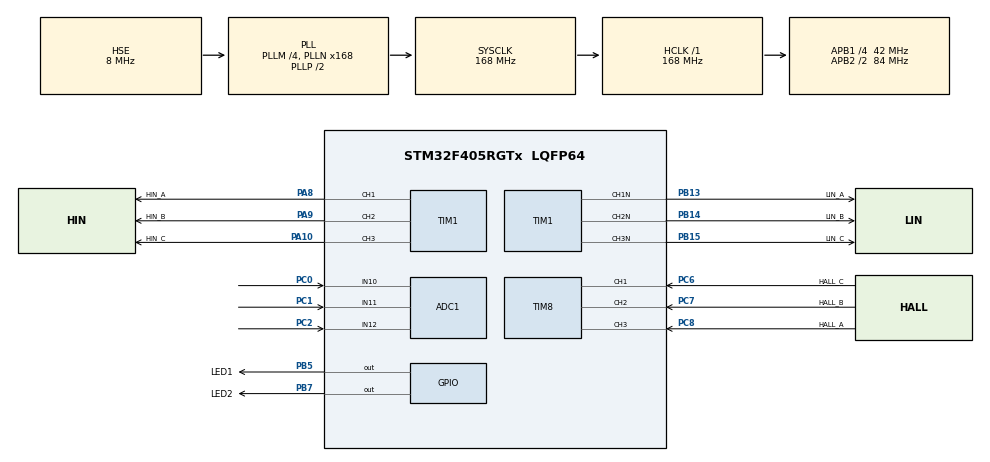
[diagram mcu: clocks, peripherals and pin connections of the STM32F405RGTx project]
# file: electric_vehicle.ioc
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ADC1.Channel-0\#ChannelRegularConversion=ADC_CHANNEL_10
ADC1.Channel-4\#ChannelInjectedConversion=ADC_CHANNEL_10
ADC1.Channel-5\#ChannelInjectedConversion=ADC_CHANNEL_11
ADC1.Channel-6\#ChannelInjectedConversion=ADC_CHANNEL_12
ADC1.DataAlign=ADC_DATAALIGN_LEFT
ADC1.ExternalTrigInjecConv=ADC_EXTERNALTRIGINJECCONV_T1_CC4
ADC1.InjNumberOfConversion=3
ADC1.InjectedConvMode=Discontinuous
ADC1.InjectedOffset-4\#ChannelInjectedConversion=0
ADC1.InjectedOffset-5\#ChannelInjectedConversion=0
ADC1.InjectedOffset-6\#ChannelInjectedConversion=0
ADC1.InjectedRank-4\#ChannelInjectedConversion=1
ADC1.InjectedRank-5\#ChannelInjectedConversion=2
ADC1.InjectedRank-6\#ChannelInjectedConversion=3
ADC1.NbrOfConversion=1
ADC1.NbrOfConversionFlag=1
ADC1.Rank-0\#ChannelRegularConversion=1
ADC1.SamplingTime-0\#ChannelRegularConversion=ADC_SAMPLETIME_3CYCLES
ADC1.SamplingTime-4\#ChannelInjectedConversion=ADC_SAMPLETIME_3CYCLES
ADC1.SamplingTime-5\#ChannelInjectedConversion=ADC_SAMPLETIME_3CYCLES
ADC1.SamplingTime-6\#ChannelInjectedConversion=ADC_SAMPLETIME_3CYCLES
ADC1.ScanConvMode=ENABLE
ADC1.master=1
ADC2.Channel-0\#ChannelRegularConversion=ADC_CHANNEL_10
ADC2.Channel-1\#ChannelInjectedConversion=ADC_CHANNEL_10
ADC2.Channel-2\#ChannelInjectedConversion=ADC_CHANNEL_11
ADC2.Channel-3\#ChannelInjectedConversion=ADC_CHANNEL_12
ADC2.DataAlign=ADC_DATAALIGN_LEFT
ADC2.ExternalTrigInjecConv=ADC_EXTERNALTRIGINJECCONV_T1_CC4
ADC2.InjNumberOfConversion=3
ADC2.InjectedConvMode=Discontinuous
ADC2.InjectedOffset-1\#ChannelInjectedConversion=0
ADC2.InjectedOffset-2\#ChannelInjectedConversion=0
ADC2.InjectedOffset-3\#ChannelInjectedConversion=0
ADC2.InjectedRank-1\#ChannelInjectedConversion=1
ADC2.InjectedRank-2\#ChannelInjectedConversion=2
ADC2.InjectedRank-3\#ChannelInjectedConversion=3
ADC2.NbrOfConversionFlag=1
ADC2.Rank-0\#ChannelRegularConversion=1
ADC2.SamplingTime-0\#ChannelRegularConversion=ADC_SAMPLETIME_3CYCLES
ADC2.SamplingTime-1\#ChannelInjectedConversion=ADC_SAMPLETIME_3CYCLES
ADC2.SamplingTime-2\#ChannelInjectedConversion=ADC_SAMPLETIME_3CYCLES
ADC2.SamplingTime-3\#ChannelInjectedConversion=ADC_SAMPLETIME_3CYCLES
ADC2.ScanConvMode=ENABLE
Mcu.Family=STM32F4
Mcu.Name=STM32F405RGTx
Mcu.Package=LQFP64
Mcu.UserConstants=PWM_PERIOD_CYCLES,ADV_TIM_CLK_MHz*1000000/PWM_FREQUENCY;M1_ENCODER_PPR,1000;PWM_FREQUENCY,16000;M1_HALL_IC_FILTER,15;DEADTIME_NS,SW_DEADTIME_NS;TIM_CLOCK_DIVIDER,1;M1_ENC_IC_FILTER,6;SW_DEADTIME_NS,30;M1_PULSE_NBR,(4*(M1_ENCODER_PPR)-1);DEAD_TIME_COUNTS,DEAD_TIME_COUNTS_1;DEAD_TIME_COUNTS_1,DEAD_TIME_ADV_TIM_CLK_MHz*DEADTIME_NS/1000;DEAD_TIME_ADV_TIM_CLK_MHz,168;M1_HALL_TIM_PERIOD,65535;ADV_TIM_CLK_MHz,168/TIM_CLOCK_DIVIDER
NVIC.ADC_IRQn=true\:1\:0\:true\:false\:true\:true\:true\:true
NVIC.PriorityGroup=NVIC_PRIORITYGROUP_4
NVIC.TIM1_UP_TIM10_IRQn=true\:0\:0\:false\:false\:true\:true\:true\:true
NVIC.TIM8_UP_TIM13_IRQn=true\:2\:0\:true\:false\:true\:true\:true\:true
PA10.GPIO_Label=HIN_C
PA10.GPIO_Speed=GPIO_SPEED_FREQ_HIGH
PA10.Signal=S_TIM1_CH3
PA13.Mode=Serial_Wire
PA13.Signal=SYS_JTMS-SWDIO
PA14.Mode=Serial_Wire
PA14.Signal=SYS_JTCK-SWCLK
PA8.GPIO_Label=HIN_A
PA8.GPIO_Speed=GPIO_SPEED_FREQ_HIGH
PA8.Signal=S_TIM1_CH1
PA9.GPIO_Label=HIN_B
PA9.GPIO_Speed=GPIO_SPEED_FREQ_HIGH
PA9.Signal=S_TIM1_CH2
PB13.GPIO_Label=LIN_A
PB13.GPIO_Speed=GPIO_SPEED_FREQ_HIGH
PB13.Mode=PWM Generation1 CH1 CH1N
PB13.Signal=TIM1_CH1N
PB14.GPIO_Label=LIN_B
PB14.GPIO_Speed=GPIO_SPEED_FREQ_HIGH
PB14.Mode=PWM Generation2 CH2 CH2N
PB14.Signal=TIM1_CH2N
PB15.GPIO_Label=LIN_C
PB15.GPIO_Speed=GPIO_SPEED_FREQ_HIGH
PB15.Mode=PWM Generation3 CH3 CH3N
PB15.Signal=TIM1_CH3N
PB5.GPIO_Label=LED1
PB5.GPIO_Speed=GPIO_SPEED_FREQ_HIGH
PB5.Signal=GPIO_Output
PB7.GPIO_Label=LED2
PB7.GPIO_Speed=GPIO_SPEED_FREQ_HIGH
PB7.Signal=GPIO_Output
PC0.Signal=ADCx_IN10
PC1.Signal=ADCx_IN11
PC2.Signal=ADCx_IN12
PC6.GPIO_Label=HALL_C
PC6.GPIO_Speed=GPIO_SPEED_FREQ_HIGH
PC6.Signal=S_TIM8_CH1
PC7.GPIO_Label=HALL_B
PC7.GPIO_Speed=GPIO_SPEED_FREQ_HIGH
PC7.Signal=S_TIM8_CH2
PC8.GPIO_Label=HALL_A
PC8.GPIO_Speed=GPIO_SPEED_FREQ_HIGH
PC8.Signal=S_TIM8_CH3
PH0-OSC_IN.Mode=HSE-External-Oscillator
PH0-OSC_IN.Signal=RCC_OSC_IN
PH1-OSC_OUT.Mode=HSE-External-Oscillator
PH1-OSC_OUT.Signal=RCC_OSC_OUT
ProjectManager.HeapSize=0x200
ProjectManager.StackSize=0x400
ProjectManager.TargetToolchain=MDK-ARM V5.32
RCC.48MHZClocksFreq_Value=48000000
RCC.AHBFreq_Value=168000000
RCC.APB1CLKDivider=RCC_HCLK_DIV4
RCC.APB1Freq_Value=42000000
RCC.APB1TimFreq_Value=84000000
RCC.APB2CLKDivider=RCC_HCLK_DIV2
RCC.APB2Freq_Value=84000000
RCC.APB2TimFreq_Value=168000000
RCC.CortexFreq_Value=168000000
RCC.HCLKFreq_Value=168000000
RCC.HSE_VALUE=8000000
RCC.HSI_VALUE=16000000
RCC.LSE_VALUE=32768
RCC.PLLM=4
RCC.PLLN=168
RCC.PLLQ=7
RCC.PLLSourceVirtual=RCC_PLLSOURCE_HSE
RCC.SYSCLKFreq_VALUE=168000000
RCC.SYSCLKSource=RCC_SYSCLKSOURCE_PLLCLK
RCC.VCOOutputFreq_Value=336000000
SH.ADCx_IN10.0=ADC1_IN10,IN10
SH.ADCx_IN10.1=ADC2_IN10,IN10
SH.ADCx_IN11.0=ADC1_IN11,IN11
SH.ADCx_IN11.1=ADC2_IN11,IN11
SH.ADCx_IN12.0=ADC1_IN12,IN12
SH.ADCx_IN12.1=ADC2_IN12,IN12
SH.S_TIM1_CH1.0=TIM1_CH1,PWM Generation1 CH1 CH1N
SH.S_TIM1_CH2.0=TIM1_CH2,PWM Generation2 CH2 CH2N
SH.S_TIM1_CH3.0=TIM1_CH3,PWM Generation3 CH3 CH3N
SH.S_TIM8_CH1.0=TIM8_CH1,Xored_Inputs_Hall_Sensor_Interface
SH.S_TIM8_CH2.0=TIM8_CH2,Xored_Inputs_Hall_Sensor_Interface
SH.S_TIM8_CH3.0=TIM8_CH3,Xored_Inputs_Hall_Sensor_Interface
STMicroelectronics.X-CUBE-ALGOBUILD.1.4.0.LibraryCcDSPOoLibraryJjDSPOoLibrary=true
TIM1.AutoReloadPreload=TIM_AUTORELOAD_PRELOAD_ENABLE
TIM1.BreakPolarity=TIM_BREAKPOLARITY_LOW
TIM1.Channel-PWM\ Generation1\ CH1\ CH1N=TIM_CHANNEL_1
TIM1.Channel-PWM\ Generation2\ CH2\ CH2N=TIM_CHANNEL_2
TIM1.Channel-PWM\ Generation3\ CH3\ CH3N=TIM_CHANNEL_3
TIM1.Channel-PWM\ Generation4\ No\ Output=TIM_CHANNEL_4
TIM1.ClockDivision=TIM_CLOCKDIVISION_DIV2
TIM1.CounterMode=TIM_COUNTERMODE_CENTERALIGNED1
TIM1.DeadTime=20
TIM1.LockLevel=TIM_LOCKLEVEL_1
TIM1.OCMode_PWM-PWM\ Generation4\ No\ Output=TIM_OCMODE_PWM2
TIM1.OffStateIDLEMode=TIM_OSSI_ENABLE
TIM1.OffStateRunMode=TIM_OSSR_ENABLE
TIM1.Period=PWM_PERIOD_CYCLES/2
TIM1.Pulse-PWM\ Generation4\ No\ Output=PWM_PERIOD_CYCLES/2-100
TIM1.RepetitionCounter=1
TIM8.AutoReloadPreload=TIM_AUTORELOAD_PRELOAD_ENABLE
TIM8.Period=M1_HALL_TIM_PERIOD
VP_STMicroelectronics.X-CUBE-ALGOBUILD_VS_DSPOoLibraryJjLibrary_1.4.0_1.4.0.Mode=DSPOoLibraryJjLibrary
VP_TIM1_VS_ClockSourceINT.Mode=Internal
VP_TIM1_VS_ClockSourceITR.Mode=TriggerSource_ITR1
VP_TIM1_VS_ControllerModeTrigger.Mode=Trigger Mode
VP_TIM1_VS_no_output4.Mode=PWM Generation4 No Output
board=custom

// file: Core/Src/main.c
/* USER CODE BEGIN Header */
/**
 ******************************************************************************
 * @file           : main.c
 * @brief          : Main program body
 ******************************************************************************
 * @attention
 *
 * Copyright (c) 2025 STMicroelectronics.
 * All rights reserved.
 *
 * This software is licensed under terms that can be found in the LICENSE file
 * in the root directory of this software component.
 * If no LICENSE file comes with this software, it is provided AS-IS.
 *
 ******************************************************************************
 */
/* USER CODE END Header */
#include "main.h"
#include "adc.h"
#include "tim.h"
#include "gpio.h"

void SystemClock_Config(void);

int main(void)
{

  /* MCU Configuration--------------------------------------------------------*/

  /* Reset of all peripherals, Initializes the Flash interface and the Systick. */
  HAL_Init();

  /* Configure the system clock */
  SystemClock_Config();

  /* Initialize all configured peripherals */
  MX_GPIO_Init();
  MX_ADC1_Init();
  MX_ADC2_Init();
  MX_TIM1_Init();
  MX_TIM8_Init();
  /* USER CODE BEGIN 2 */

    SEGGER_RTT_printf(0, "printf Test: %%c,S' : %c.\r\n", 'S'); /* printf Test: %c,'S' : S. */
    LED1(GPIO_PIN_SET);

  /* USER CODE END 2 */

  /* Infinite loop */
    while (1) {

    }
}

void SystemClock_Config(void)
{
  RCC_OscInitTypeDef RCC_OscInitStruct = {0};
  RCC_ClkInitTypeDef RCC_ClkInitStruct = {0};

  /** Configure the main internal regulator output voltage
  */
  __HAL_RCC_PWR_CLK_ENABLE();
  __HAL_PWR_VOLTAGESCALING_CONFIG(PWR_REGULATOR_VOLTAGE_SCALE1);

  /** Initializes the RCC Oscillators according to the specified parameters
  * in the RCC_OscInitTypeDef structure.
  */
  RCC_OscInitStruct.OscillatorType = RCC_OSCILLATORTYPE_HSE;
  RCC_OscInitStruct.HSEState = RCC_HSE_ON;
  RCC_OscInitStruct.PLL.PLLState = RCC_PLL_ON;
  RCC_OscInitStruct.PLL.PLLSource = RCC_PLLSOURCE_HSE;
  RCC_OscInitStruct.PLL.PLLM = 4;
  RCC_OscInitStruct.PLL.PLLN = 168;
  RCC_OscInitStruct.PLL.PLLP = RCC_PLLP_DIV2;
  RCC_OscInitStruct.PLL.PLLQ = 7;
  if (HAL_RCC_OscConfig(&RCC_OscInitStruct) != HAL_OK)
  {
    Error_Handler();
  }

  /** Initializes the CPU, AHB and APB buses clocks
  */
  RCC_ClkInitStruct.ClockType = RCC_CLOCKTYPE_HCLK|RCC_CLOCKTYPE_SYSCLK
                              |RCC_CLOCKTYPE_PCLK1|RCC_CLOCKTYPE_PCLK2;
  RCC_ClkInitStruct.SYSCLKSource = RCC_SYSCLKSOURCE_PLLCLK;
  RCC_ClkInitStruct.AHBCLKDivider = RCC_SYSCLK_DIV1;
  RCC_ClkInitStruct.APB1CLKDivider = RCC_HCLK_DIV4;
  RCC_ClkInitStruct.APB2CLKDivider = RCC_HCLK_DIV2;

  if (HAL_RCC_ClockConfig(&RCC_ClkInitStruct, FLASH_LATENCY_5) != HAL_OK)
  {
    Error_Handler();
  }
}

void Error_Handler(void)
{
    __disable_irq();
    while (1) {
    }
}
